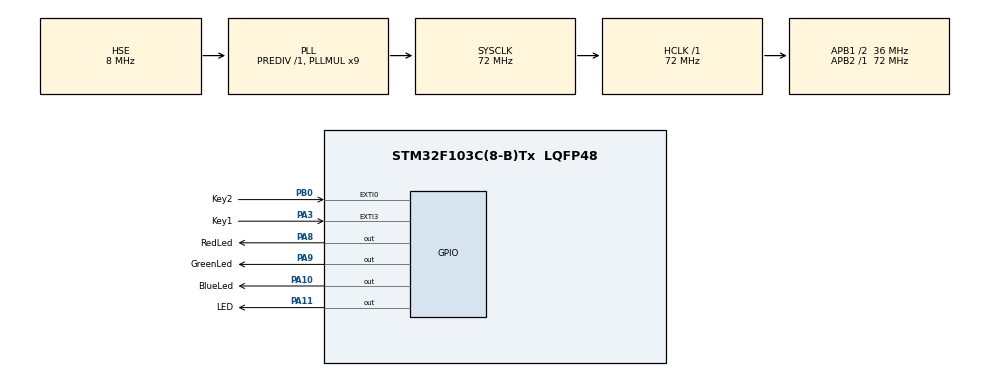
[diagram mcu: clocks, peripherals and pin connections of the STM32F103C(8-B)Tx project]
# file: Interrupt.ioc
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Mcu.Family=STM32F1
Mcu.Name=STM32F103C(8-B)Tx
Mcu.Package=LQFP48
NVIC.EXTI0_IRQn=true\:13\:0\:true\:false\:true\:true\:true\:true
NVIC.EXTI3_IRQn=true\:14\:0\:true\:false\:true\:true\:true\:true
NVIC.PriorityGroup=NVIC_PRIORITYGROUP_4
NVIC.TIM3_IRQn=true\:0\:0\:false\:false\:true\:true\:true\:true
PA10.GPIO_Label=BlueLed
PA10.Signal=GPIO_Output
PA11.GPIO_Label=LED
PA11.Signal=GPIO_Output
PA13.Mode=Serial_Wire
PA13.Signal=SYS_JTMS-SWDIO
PA14.Mode=Serial_Wire
PA14.Signal=SYS_JTCK-SWCLK
PA3.GPIO_Label=Key1
PA3.GPIO_ModeDefaultEXTI=GPIO_MODE_IT_FALLING
PA3.GPIO_PuPd=GPIO_PULLUP
PA3.Signal=GPXTI3
PA8.GPIO_Label=RedLed
PA8.Signal=GPIO_Output
PA9.GPIO_Label=GreenLed
PA9.Signal=GPIO_Output
PB0.GPIO_Label=Key2
PB0.GPIO_ModeDefaultEXTI=GPIO_MODE_IT_FALLING
PB0.GPIO_PuPd=GPIO_PULLUP
PB0.Signal=GPXTI0
PD0-OSC_IN.Mode=HSE-External-Oscillator
PD0-OSC_IN.Signal=RCC_OSC_IN
PD1-OSC_OUT.Mode=HSE-External-Oscillator
PD1-OSC_OUT.Signal=RCC_OSC_OUT
ProjectManager.HeapSize=0x200
ProjectManager.StackSize=0x400
ProjectManager.TargetToolchain=STM32CubeIDE
RCC.AHBFreq_Value=72000000
RCC.APB1CLKDivider=RCC_HCLK_DIV2
RCC.APB1Freq_Value=36000000
RCC.APB1TimFreq_Value=72000000
RCC.APB2Freq_Value=72000000
RCC.APB2TimFreq_Value=72000000
RCC.HCLKFreq_Value=72000000
RCC.PLLMUL=RCC_PLL_MUL9
RCC.PLLSourceVirtual=RCC_PLLSOURCE_HSE
RCC.SYSCLKFreq_VALUE=72000000
RCC.SYSCLKSource=RCC_SYSCLKSOURCE_PLLCLK
RCC.USBFreq_Value=72000000
TIM3.AutoReloadPreload=TIM_AUTORELOAD_PRELOAD_ENABLE
TIM3.Period=10000-1
TIM3.Prescaler=7200-1
VP_TIM3_VS_ClockSourceINT.Mode=Internal
board=custom

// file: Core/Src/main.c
/* USER CODE BEGIN Header */
/**
  ******************************************************************************
  * @file           : main.c
  * @brief          : Main program body
  ******************************************************************************
  * @attention
  *
  * Copyright (c) 2025 STMicroelectronics.
  * All rights reserved.
  *
  * This software is licensed under terms that can be found in the LICENSE file
  * in the root directory of this software component.
  * If no LICENSE file comes with this software, it is provided AS-IS.
  *
  ******************************************************************************
  */
/* USER CODE END Header */
#include "main.h"

TIM_HandleTypeDef htim3;

/* USER CODE BEGIN PV */
typedef enum{
	Red,
	Green,
	Blue,
}LEDCol;

LEDCol LedColor = Red;

//改变定时器频率相关变量
Period_t TimePeriod = Period_1Sec;//初始彩灯循环周期为1s

const uint16_t ARR[3]={
		10000-1,//1Hz
		20000-1,//0.5Hz
		40000-1,//0.25Hz
};

/* USER CODE END PV */

void SystemClock_Config(void);
static void MX_GPIO_Init(void);
static void MX_TIM3_Init(void);

/* USER CODE BEGIN 0 */
__weak void HAL_TIM_PeriodElapsedCallback(TIM_HandleTypeDef *htim){
	if(htim == &htim3){
		switch(LedColor){//根据定时器的时间循环依次显示 红 绿 蓝三个led灯
		case Red:
			HAL_GPIO_WritePin(BlueLed_GPIO_Port, BlueLed_Pin, GPIO_PIN_RESET);
			HAL_GPIO_WritePin(RedLed_GPIO_Port, RedLed_Pin, GPIO_PIN_SET);
			LedColor = Green;
			break;
		case Green:
			HAL_GPIO_WritePin(RedLed_GPIO_Port, RedLed_Pin, GPIO_PIN_RESET);
			HAL_GPIO_WritePin(GreenLed_GPIO_Port, GreenLed_Pin, GPIO_PIN_SET);
			LedColor = Blue;
			break;
		case Blue:
			HAL_GPIO_WritePin(GreenLed_GPIO_Port, GreenLed_Pin, GPIO_PIN_RESET);
			HAL_GPIO_WritePin(BlueLed_GPIO_Port, BlueLed_Pin, GPIO_PIN_SET);
			LedColor = Red;
			break;
		}
	}
}

void ChangeTIMFreq(Period_t PT) {
    __HAL_TIM_SET_AUTORELOAD(&htim3, ARR[PT]);  // 直接更新 ARR 寄存器
    // 不需要 Stop/Start，除非你要改 PSC 或模式
}/* USER CODE END 0 */

int main(void)
{

  /* MCU Configuration--------------------------------------------------------*/

  /* Reset of all peripherals, Initializes the Flash interface and the Systick. */
  HAL_Init();

  /* Configure the system clock */
  SystemClock_Config();

  /* Initialize all configured peripherals */
  MX_GPIO_Init();
  MX_TIM3_Init();
  /* USER CODE BEGIN 2 */
  HAL_TIM_Base_Start_IT(&htim3);
  /* USER CODE END 2 */

  /* Infinite loop */
  while (1)
  {

  }
}

void SystemClock_Config(void)
{
  RCC_OscInitTypeDef RCC_OscInitStruct = {0};
  RCC_ClkInitTypeDef RCC_ClkInitStruct = {0};

  /** Initializes the RCC Oscillators according to the specified parameters
  * in the RCC_OscInitTypeDef structure.
  */
  RCC_OscInitStruct.OscillatorType = RCC_OSCILLATORTYPE_HSE;
  RCC_OscInitStruct.HSEState = RCC_HSE_ON;
  RCC_OscInitStruct.HSEPredivValue = RCC_HSE_PREDIV_DIV1;
  RCC_OscInitStruct.HSIState = RCC_HSI_ON;
  RCC_OscInitStruct.PLL.PLLState = RCC_PLL_ON;
  RCC_OscInitStruct.PLL.PLLSource = RCC_PLLSOURCE_HSE;
  RCC_OscInitStruct.PLL.PLLMUL = RCC_PLL_MUL9;
  if (HAL_RCC_OscConfig(&RCC_OscInitStruct) != HAL_OK)
  {
    Error_Handler();
  }

  /** Initializes the CPU, AHB and APB buses clocks
  */
  RCC_ClkInitStruct.ClockType = RCC_CLOCKTYPE_HCLK|RCC_CLOCKTYPE_SYSCLK
                              |RCC_CLOCKTYPE_PCLK1|RCC_CLOCKTYPE_PCLK2;
  RCC_ClkInitStruct.SYSCLKSource = RCC_SYSCLKSOURCE_PLLCLK;
  RCC_ClkInitStruct.AHBCLKDivider = RCC_SYSCLK_DIV1;
  RCC_ClkInitStruct.APB1CLKDivider = RCC_HCLK_DIV2;
  RCC_ClkInitStruct.APB2CLKDivider = RCC_HCLK_DIV1;

  if (HAL_RCC_ClockConfig(&RCC_ClkInitStruct, FLASH_LATENCY_2) != HAL_OK)
  {
    Error_Handler();
  }
}

static void MX_TIM3_Init(void)
{

  TIM_ClockConfigTypeDef sClockSourceConfig = {0};
  TIM_MasterConfigTypeDef sMasterConfig = {0};

  htim3.Instance = TIM3;
  htim3.Init.Prescaler = 7200-1;
  htim3.Init.CounterMode = TIM_COUNTERMODE_UP;
  htim3.Init.Period = 10000-1;
  htim3.Init.ClockDivision = TIM_CLOCKDIVISION_DIV1;
  htim3.Init.AutoReloadPreload = TIM_AUTORELOAD_PRELOAD_ENABLE;
  if (HAL_TIM_Base_Init(&htim3) != HAL_OK)
  {
    Error_Handler();
  }
  sClockSourceConfig.ClockSource = TIM_CLOCKSOURCE_INTERNAL;
  if (HAL_TIM_ConfigClockSource(&htim3, &sClockSourceConfig) != HAL_OK)
  {
    Error_Handler();
  }
  sMasterConfig.MasterOutputTrigger = TIM_TRGO_RESET;
  sMasterConfig.MasterSlaveMode = TIM_MASTERSLAVEMODE_DISABLE;
  if (HAL_TIMEx_MasterConfigSynchronization(&htim3, &sMasterConfig) != HAL_OK)
  {
    Error_Handler();
  }

}

static void MX_GPIO_Init(void)
{
  GPIO_InitTypeDef GPIO_InitStruct = {0};

  /* GPIO Ports Clock Enable */
  __HAL_RCC_GPIOD_CLK_ENABLE();
  __HAL_RCC_GPIOA_CLK_ENABLE();
  __HAL_RCC_GPIOB_CLK_ENABLE();

  /*Configure GPIO pin Output Level */
  HAL_GPIO_WritePin(GPIOA, RedLed_Pin|GreenLed_Pin|BlueLed_Pin|LED_Pin, GPIO_PIN_RESET);

  /*Configure GPIO pin : Key1_Pin */
  GPIO_InitStruct.Pin = Key1_Pin;
  GPIO_InitStruct.Mode = GPIO_MODE_IT_FALLING;
  GPIO_InitStruct.Pull = GPIO_PULLUP;
  HAL_GPIO_Init(Key1_GPIO_Port, &GPIO_InitStruct);

  /*Configure GPIO pin : Key2_Pin */
  GPIO_InitStruct.Pin = Key2_Pin;
  GPIO_InitStruct.Mode = GPIO_MODE_IT_FALLING;
  GPIO_InitStruct.Pull = GPIO_PULLUP;
  HAL_GPIO_Init(Key2_GPIO_Port, &GPIO_InitStruct);

  /*Configure GPIO pins : RedLed_Pin GreenLed_Pin BlueLed_Pin LED_Pin */
  GPIO_InitStruct.Pin = RedLed_Pin|GreenLed_Pin|BlueLed_Pin|LED_Pin;
  GPIO_InitStruct.Mode = GPIO_MODE_OUTPUT_PP;
  GPIO_InitStruct.Pull = GPIO_NOPULL;
  GPIO_InitStruct.Speed = GPIO_SPEED_FREQ_LOW;
  HAL_GPIO_Init(GPIOA, &GPIO_InitStruct);

  /* EXTI interrupt init*/
  HAL_NVIC_SetPriority(EXTI0_IRQn, 13, 0);
  HAL_NVIC_EnableIRQ(EXTI0_IRQn);

  HAL_NVIC_SetPriority(EXTI3_IRQn, 14, 0);
  HAL_NVIC_EnableIRQ(EXTI3_IRQn);

}

void Error_Handler(void)
{
  __disable_irq();
  while (1)
  {
  }
}
